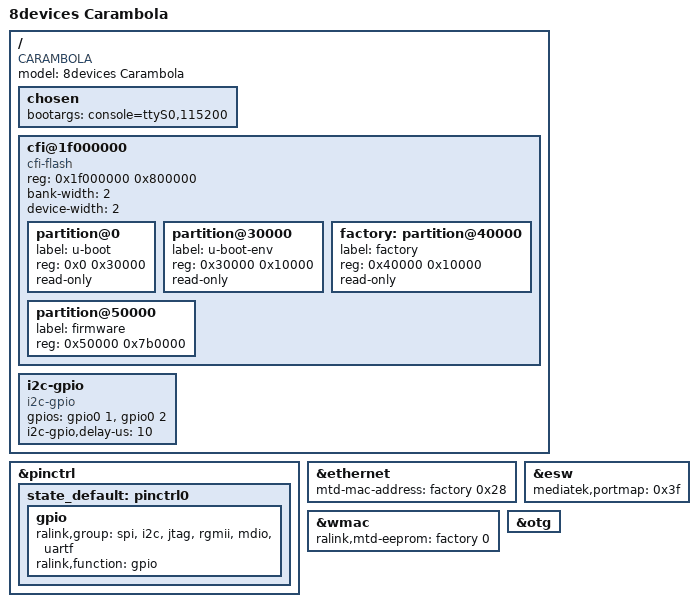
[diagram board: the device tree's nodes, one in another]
/dts-v1/;

#include "rt3050.dtsi"

/ {
	compatible = "CARAMBOLA", "ralink,rt3050-soc";
	model = "8devices Carambola";

	chosen {
		bootargs = "console=ttyS0,115200";
	};

	cfi@1f000000 {
		compatible = "cfi-flash";
		reg = <0x1f000000 0x800000>;
		bank-width = <2>;
		device-width = <2>;
		#address-cells = <1>;
		#size-cells = <1>;

		partition@0 {
			label = "u-boot";
			reg = <0x0 0x30000>;
			read-only;
		};

		partition@30000 {
			label = "u-boot-env";
			reg = <0x30000 0x10000>;
			read-only;
		};

		factory: partition@40000 {
			label = "factory";
			reg = <0x40000 0x10000>;
			read-only;
		};

		partition@50000 {
			label = "firmware";
			reg = <0x50000 0x7b0000>;
		};
	};

	i2c-gpio {
		compatible = "i2c-gpio";
		gpios = <&gpio0 1 0 &gpio0 2 0>;
		i2c-gpio,delay-us = <10>;
	};
};

&pinctrl {
	state_default: pinctrl0 {
		gpio {
			ralink,group = "spi", "i2c", "jtag", "rgmii", "mdio", "uartf";
			ralink,function = "gpio";
		};
	};
};

&ethernet {
	mtd-mac-address = <&factory 0x28>;
};

&esw {
	mediatek,portmap = <0x3f>;
};

&wmac {
	ralink,mtd-eeprom = <&factory 0>;
};

&otg {
	status = "okay";
};
